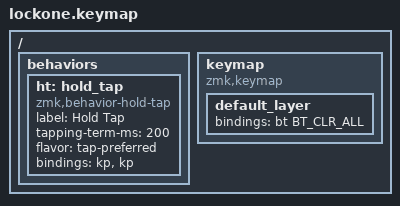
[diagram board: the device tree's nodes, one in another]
/*
 * Copyright (c) 2020 The ZMK Contributors
 *
 * SPDX-License-Identifier: MIT
 */

#include <behaviors.dtsi>
#include <dt-bindings/zmk/keys.h>
#include <dt-bindings/zmk/bt.h>
#include <dt-bindings/zmk/outputs.h>

#define DEF 0

/ {
    behaviors {
        ht: hold_tap {
            compatible = "zmk,behavior-hold-tap";
            label = "Hold Tap";
            #binding-cells = <2>;
            tapping-term-ms = <200>;
            flavor = "tap-preferred";
            bindings = <&kp>, <&kp>;
        };
    };

    keymap {
        compatible = "zmk,keymap";

        default_layer {
            bindings = <
			&bt BT_CLR_ALL
            >;
        };
    };
};
